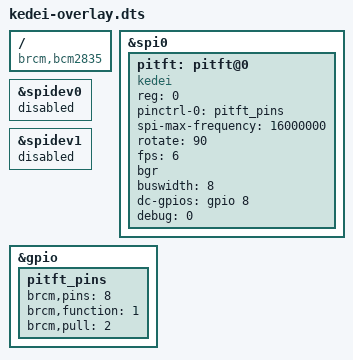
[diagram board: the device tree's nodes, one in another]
/dts-v1/;
/plugin/;
 
/ {
	compatible = "brcm,bcm2835", "brcm,bcm2708", "brcm,bcm2709";


	fragment@0 {
		target = <&spi0>;
		__overlay__ {
			status = "okay";
		};
	};

	fragment@1 {
		target = <&spidev0>;
		__overlay__ {
			status = "disabled";
		};
	};

	fragment@2 {
		target = <&spidev1>;
		__overlay__ {
			status = "disabled";
		};
	};

	fragment@3 {
		target = <&gpio>;
		__overlay__ {
			pitft_pins: pitft_pins {
				brcm,pins = <8>;
				brcm,function = <1>; /* out */
				brcm,pull = <2>; /* pullup */
			};
		};
	};

	fragment@4 {
		target = <&spi0>;
		__overlay__ {
			/* needed to avoid dtc warning */
			#address-cells = <1>;
			#size-cells = <0>;

			pitft: pitft@0{
				compatible = "kedei";
				reg = <0>;
				pinctrl-names = "default";
				pinctrl-0 = <&pitft_pins>;

				spi-max-frequency = <16000000>;
				rotate = <90>;
				fps = <6>;
				bgr;
				buswidth = <8>;
				dc-gpios = <&gpio 8 0>;
				debug = <0>;
			};
		};
	};
};
